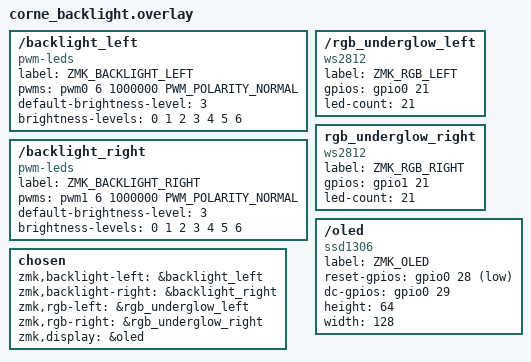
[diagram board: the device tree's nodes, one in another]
/backlight_left {
    compatible = "pwm-leds";
    label = "ZMK_BACKLIGHT_LEFT";
    pwms = <&pwm0 6 1000000 PWM_POLARITY_NORMAL>; /* PWM пин для левого backlight */
    default-brightness-level = <3>;
    brightness-levels = <0 1 2 3 4 5 6>;
};

/backlight_right {
    compatible = "pwm-leds";
    label = "ZMK_BACKLIGHT_RIGHT";
    pwms = <&pwm1 6 1000000 PWM_POLARITY_NORMAL>; /* PWM пин для правого backlight */
    default-brightness-level = <3>;
    brightness-levels = <0 1 2 3 4 5 6>;
};

/rgb_underglow_left {
    compatible = "ws2812";
    label = "ZMK_RGB_LEFT";
    gpios = <&gpio0 21 GPIO_ACTIVE_HIGH>; /* Подключение underglow left */
    #led-cells = <3>;
    led-count = <21>;
};

rgb_underglow_right {
    compatible = "ws2812";
    label = "ZMK_RGB_RIGHT";
    gpios = <&gpio1 21 GPIO_ACTIVE_HIGH>; /* Подключение underglow right */
    #led-cells = <3>;
    led-count = <21>;
};

/oled {
    compatible = "ssd1306";
    label = "ZMK_OLED";
    reset-gpios = <&gpio0 28 GPIO_ACTIVE_LOW>; 
    dc-gpios = <&gpio0 29 GPIO_ACTIVE_HIGH>;
    height = <64>;
    width = <128>;
};

chosen {
    zmk,backlight-left = &backlight_left;
    zmk,backlight-right = &backlight_right;
    zmk,rgb-left = &rgb_underglow_left;
    zmk,rgb-right = &rgb_underglow_right;
    zmk,display = &oled;
};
